# K210 register map
Vendor: Canaan Inc.; File version: 1.0
Kendryte K210 64-bit RISC-V CPU
Registers are 32-bit, read-write, reset 0x0 unless marked. A register's access mark holds for its fields unless they carry their own. Offsets are from the block's base; lines under a group give offsets from that group; [hi:lo] are bit positions; {n}, {i} and the like mark numbered series; 'fields as' and 'values as' point back to an identical list; <NAME> marks a mode.

## Memory map
0x02000000 CLINT — Core Local Interruptor
0x0C000000 PLIC — Platform-Level Interrupt Controller
0x38000000 UARTHS — High-speed UART
0x38001000 GPIOHS — High-speed GPIO
0x50000000 DMAC — Direct Memory Access Controller
0x50200000 GPIO — General Purpose Input/Output Interface
0x50210000 UART1 — Universal Asynchronous Receiver-Transmitter 1
0x50220000 UART2 — Universal Asynchronous Receiver-Transmitter 2
0x50230000 UART3 — Universal Asynchronous Receiver-Transmitter 3
0x50240000 SPI2 — Serial Peripheral Interface 2 (slave)
0x50250000 I2S0 — Inter-Integrated Sound Interface 0
0x50260000 I2S1 — Inter-Integrated Sound Interface 1
0x50270000 I2S2 — Inter-Integrated Sound Interface 2
0x50280000 I2C0 — Inter-Integrated Circuit Bus 0
0x50290000 I2C1 — Inter-Integrated Circuit Bus 1
0x502A0000 I2C2 — Inter-Integrated Circuit Bus 2
0x502B0000 FPIOA — Field Programmable IO Array
0x502C0000 SHA256 — SHA256 Accelerator
0x502D0000 TIMER0
0x502E0000 TIMER1
0x502F0000 TIMER2
0x50400000 WDT0 — Watchdog Timer 0
0x50410000 WDT1 — Watchdog Timer 1
0x50420000 OTP — One-Time Programmable Memory Controller
0x50430000 DVP — Digital Video Port
0x50440000 SYSCTL — System Controller
0x50450000 AES — AES Accelerator
0x50460000 RTC — Real Time Clock
0x52000000 SPI0 — Serial Peripheral Interface 0 (master)
0x53000000 SPI1 — Serial Peripheral Interface 1 (master)
0x54000000 SPI3 — Serial Peripheral Interface 3 (master)

## CLINT — Core Local Interruptor
Base 0x02000000
Same registers: PLIC 0x0C000000, DMAC 0x50000000, GPIO 0x50200000, UART1 0x50210000, UART2 0x50220000, UART3 0x50230000, SPI2 0x50240000, SHA256 0x502C0000, WDT0 0x50400000, WDT1 0x50410000, OTP 0x50420000, DVP 0x50430000, AES 0x50450000, RTC 0x50460000, SPI3 0x54000000
0x00 dummy — Dummy register: this peripheral is not implemented yet

## UARTHS — High-speed UART
Base 0x38000000
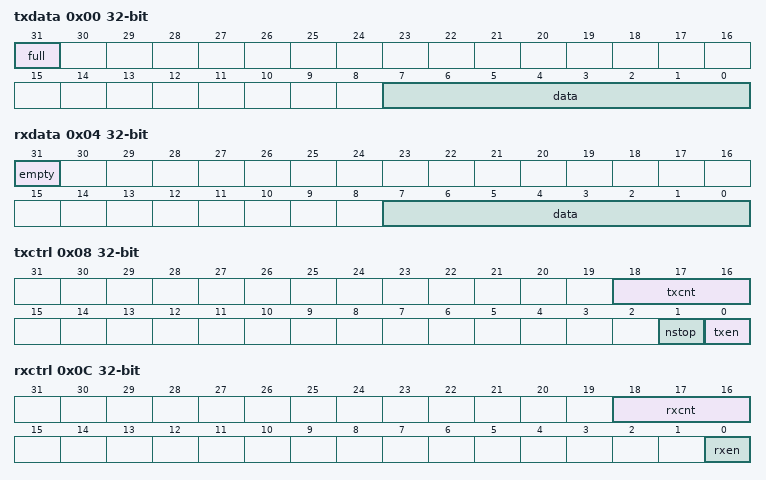
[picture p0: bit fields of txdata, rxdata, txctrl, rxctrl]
0x00 txdata — Transmit Data Register
  [31] full — Transmit FIFO full
  [7:0] data — Transmit data
0x04 rxdata — Receive Data Register
  [31] empty — Receive FIFO empty
  [7:0] data — Received data
0x08 txctrl — Transmit Control Register
  [18:16] txcnt — Transmit watermark level
  [1] nstop — Number of stop bits
  [0] txen — Transmit enable
0x0C rxctrl — Receive Control Register
  [18:16] rxcnt — Receive watermark level
  [0] rxen — Receive enable
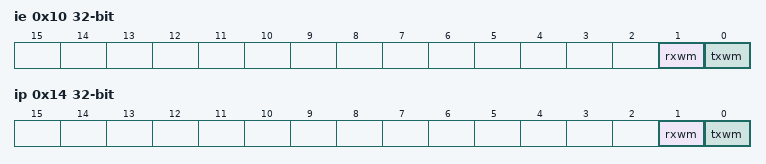
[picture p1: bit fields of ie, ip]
0x10 ie — Interrupt Enable Register
  [1] rxwm — Receive watermark interrupt enable
  [0] txwm — Transmit watermark interrupt enable
0x14 ip — Interrupt Pending Register
  [1] rxwm — Receive watermark interrupt pending
  [0] txwm — Transmit watermark interrupt pending
0x18 div — Baud Rate Divisor Register
  [15:0] div — Baud rate divisor

## GPIOHS — High-speed GPIO
Base 0x38001000
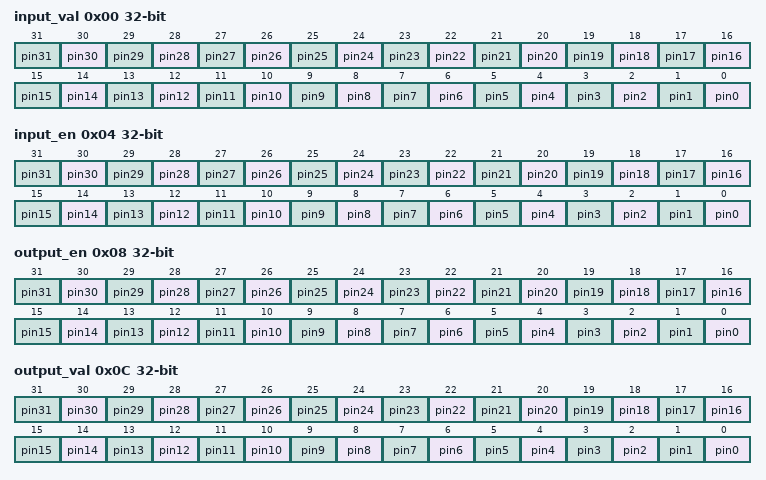
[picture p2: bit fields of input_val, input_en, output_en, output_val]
0x00 input_val — Input Value Register
  [n] pin{n} (n=0..31)
0x04 input_en — Pin Input Enable Register
  [n] pin{n} (n=0..31)
0x08 output_en — Pin Output Enable Register
  [n] pin{n} (n=0..31)
0x0C output_val — Output Value Register
  [n] pin{n} (n=0..31)
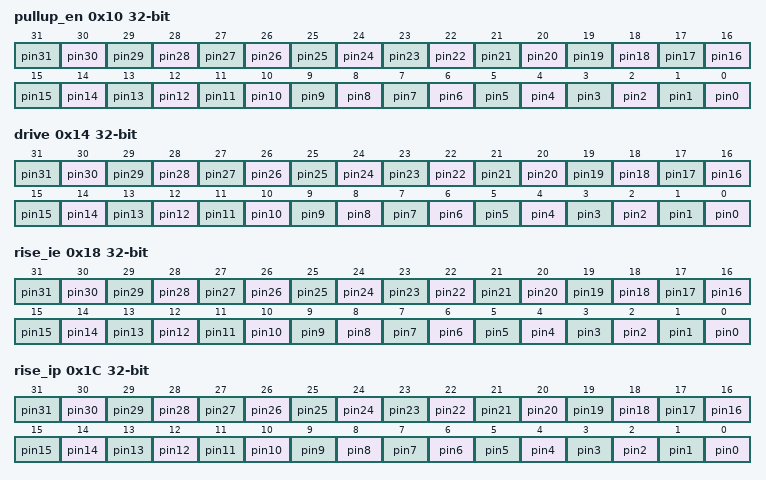
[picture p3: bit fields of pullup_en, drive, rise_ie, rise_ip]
0x10 pullup_en — Internal Pull-Up Enable Register
  [n] pin{n} (n=0..31)
0x14 drive — Drive Strength Register
  [n] pin{n} (n=0..31)
0x18 rise_ie — Rise Interrupt Enable Register
  [n] pin{n} (n=0..31)
0x1C rise_ip — Rise Interrupt Pending Register
  [n] pin{n} (n=0..31)
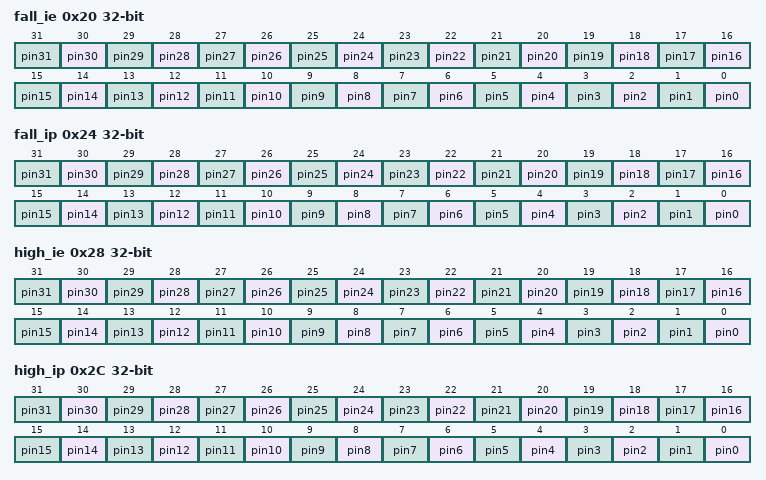
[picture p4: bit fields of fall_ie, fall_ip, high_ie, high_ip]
0x20 fall_ie — Fall Interrupt Enable Register
  [n] pin{n} (n=0..31)
0x24 fall_ip — Fall Interrupt Pending Register
  [n] pin{n} (n=0..31)
0x28 high_ie — High Interrupt Enable Register
  [n] pin{n} (n=0..31)
0x2C high_ip — High Interrupt Pending Register
  [n] pin{n} (n=0..31)
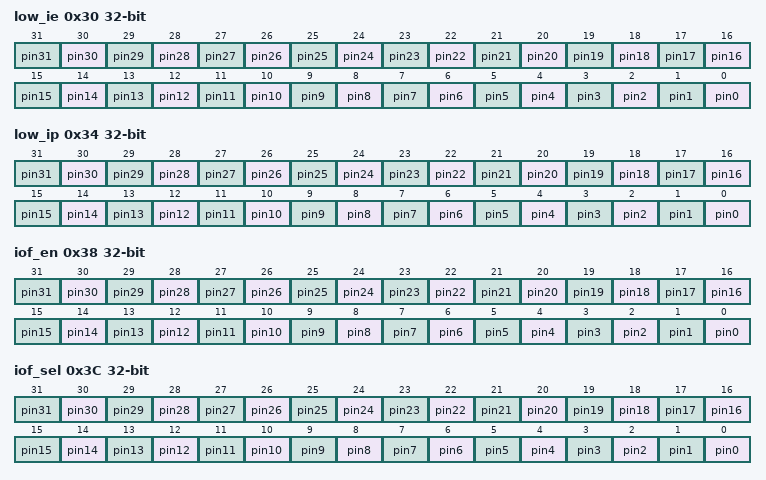
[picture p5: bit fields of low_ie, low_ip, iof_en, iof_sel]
0x30 low_ie — Low Interrupt Enable Register
  [n] pin{n} (n=0..31)
0x34 low_ip — Low Interrupt Pending Register
  [n] pin{n} (n=0..31)
0x38 iof_en — HW I/O Function Enable Register
  [n] pin{n} (n=0..31)
0x3C iof_sel — HW I/O Function Select Register
  [n] pin{n} (n=0..31)
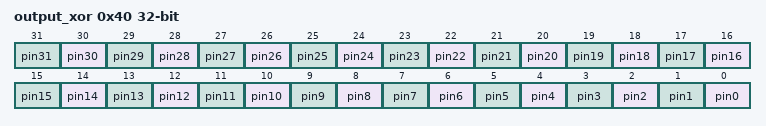
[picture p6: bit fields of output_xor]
0x40 output_xor — Output XOR (invert) Register
  [n] pin{n} (n=0..31)
